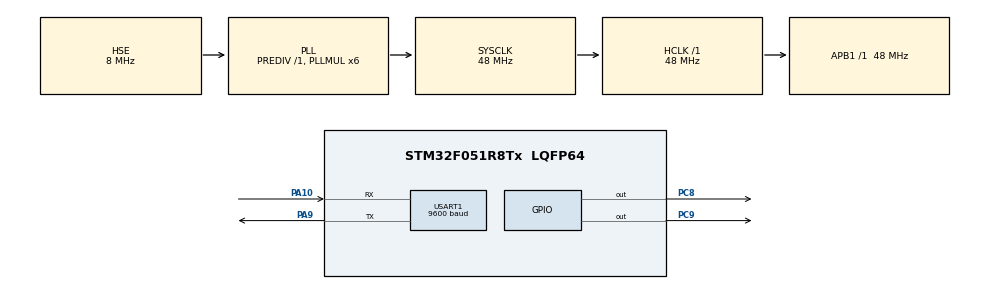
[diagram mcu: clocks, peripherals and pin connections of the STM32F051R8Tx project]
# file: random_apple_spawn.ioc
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Dma.Request0=USART1_RX
Dma.USART1_RX.0.Direction=DMA_PERIPH_TO_MEMORY
Dma.USART1_RX.0.Instance=DMA1_Channel3
Dma.USART1_RX.0.MemDataAlignment=DMA_MDATAALIGN_BYTE
Dma.USART1_RX.0.MemInc=DMA_MINC_ENABLE
Dma.USART1_RX.0.Mode=DMA_NORMAL
Dma.USART1_RX.0.PeriphDataAlignment=DMA_PDATAALIGN_BYTE
Dma.USART1_RX.0.PeriphInc=DMA_PINC_DISABLE
Dma.USART1_RX.0.Priority=DMA_PRIORITY_LOW
Mcu.Family=STM32F0
Mcu.Name=STM32F051R8Tx
Mcu.Package=LQFP64
NVIC.DMA1_Channel2_3_IRQn=true\:0\:0\:false\:false\:true\:false\:true\:true
NVIC.USART1_IRQn=true\:0\:0\:false\:false\:true\:true\:true\:true
PA10.Mode=Asynchronous
PA10.Signal=USART1_RX
PA13.Mode=Serial_Wire
PA13.Signal=SYS_SWDIO
PA14.Mode=Serial_Wire
PA14.Signal=SYS_SWCLK
PA9.Mode=Asynchronous
PA9.Signal=USART1_TX
PC8.Signal=GPIO_Output
PC9.Signal=GPIO_Output
PF0-OSC_IN.Mode=HSE-External-Oscillator
PF0-OSC_IN.Signal=RCC_OSC_IN
PF1-OSC_OUT.Mode=HSE-External-Oscillator
PF1-OSC_OUT.Signal=RCC_OSC_OUT
ProjectManager.HeapSize=0x200
ProjectManager.StackSize=0x400
ProjectManager.TargetToolchain=STM32CubeIDE
RCC.AHBFreq_Value=48000000
RCC.APB1Freq_Value=48000000
RCC.APB1TimFreq_Value=48000000
RCC.HCLKFreq_Value=48000000
RCC.PLLMUL=RCC_PLL_MUL6
RCC.PLLSourceVirtual=RCC_PLLSOURCE_HSE
RCC.SYSCLKFreq_VALUE=48000000
RCC.SYSCLKSource=RCC_SYSCLKSOURCE_PLLCLK
USART1.BaudRate=9600
USART1.VirtualMode-Asynchronous=VM_ASYNC
board=custom

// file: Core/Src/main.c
/* USER CODE BEGIN Header */
/**
  ******************************************************************************
  * @file           : main.c
  * @brief          : Main program body
  ******************************************************************************
  * @attention
  *
  * Copyright (c) 2025 STMicroelectronics.
  * All rights reserved.
  *
  * This software is licensed under terms that can be found in the LICENSE file
  * in the root directory of this software component.
  * If no LICENSE file comes with this software, it is provided AS-IS.
  *
  ******************************************************************************
  */
/* USER CODE END Header */
#include "main.h"
#include <stdio.h>
#include <stdlib.h>  // Для rand()
#include <time.h>    // Для ініціалізації випадкових чисел

UART_HandleTypeDef huart1;
DMA_HandleTypeDef hdma_usart1_rx;
uint8_t rxdata; // Буфер для прийому UART
int apple_x = 0, apple_y = 0; // Координати яблука

void SystemClock_Config(void);
static void MX_GPIO_Init(void);
static void MX_DMA_Init(void);
static void MX_USART1_UART_Init(void);
void generate_apple();
/* USER CODE BEGIN PFP */
void HAL_UART_RxCpltCallback(UART_HandleTypeDef *huart) {
    if (huart->Instance == USART1) {
        if (rxdata == 'E' || rxdata == 'e') { // Якщо натиснули E
            generate_apple(); // Генеруємо яблуко
        }
        HAL_UART_Receive_IT(&huart1, &rxdata, 1); // Продовжуємо прийом
    }
}

/* USER CODE END PFP */

/* USER CODE BEGIN 0 */
void generate_apple() {
    apple_x = rand() % 20; // Діапазон 0-19
    apple_y = rand() % 15; // Діапазон 0-14
    char buffer[30];
    int len = snprintf(buffer, sizeof(buffer), "Apple: X=%d, Y=%d\r\n", apple_x, apple_y);
    HAL_UART_Transmit(&huart1, (uint8_t *)buffer, len, HAL_MAX_DELAY);
}
/* USER CODE END 0 */

int main(void)
{

  /* MCU Configuration--------------------------------------------------------*/

  /* Reset of all peripherals, Initializes the Flash interface and the Systick. */
  HAL_Init();

  /* Configure the system clock */
  SystemClock_Config();

  /* Initialize all configured peripherals */
  MX_GPIO_Init();
  MX_DMA_Init();
  MX_USART1_UART_Init();
  srand(HAL_GetTick()); // Ініціалізація випадкових чисел

  /* Infinite loop */
  while (1)
  {
	  HAL_Delay(100); // Маленька пауза для стабільності
  }
}

void SystemClock_Config(void)
{
  RCC_OscInitTypeDef RCC_OscInitStruct = {0};
  RCC_ClkInitTypeDef RCC_ClkInitStruct = {0};
  RCC_PeriphCLKInitTypeDef PeriphClkInit = {0};

  /** Initializes the RCC Oscillators according to the specified parameters
  * in the RCC_OscInitTypeDef structure.
  */
  RCC_OscInitStruct.OscillatorType = RCC_OSCILLATORTYPE_HSE;
  RCC_OscInitStruct.HSEState = RCC_HSE_ON;
  RCC_OscInitStruct.PLL.PLLState = RCC_PLL_ON;
  RCC_OscInitStruct.PLL.PLLSource = RCC_PLLSOURCE_HSE;
  RCC_OscInitStruct.PLL.PLLMUL = RCC_PLL_MUL6;
  RCC_OscInitStruct.PLL.PREDIV = RCC_PREDIV_DIV1;
  if (HAL_RCC_OscConfig(&RCC_OscInitStruct) != HAL_OK)
  {
    Error_Handler();
  }

  /** Initializes the CPU, AHB and APB buses clocks
  */
  RCC_ClkInitStruct.ClockType = RCC_CLOCKTYPE_HCLK|RCC_CLOCKTYPE_SYSCLK
                              |RCC_CLOCKTYPE_PCLK1;
  RCC_ClkInitStruct.SYSCLKSource = RCC_SYSCLKSOURCE_PLLCLK;
  RCC_ClkInitStruct.AHBCLKDivider = RCC_SYSCLK_DIV1;
  RCC_ClkInitStruct.APB1CLKDivider = RCC_HCLK_DIV1;

  if (HAL_RCC_ClockConfig(&RCC_ClkInitStruct, FLASH_LATENCY_1) != HAL_OK)
  {
    Error_Handler();
  }
  PeriphClkInit.PeriphClockSelection = RCC_PERIPHCLK_USART1;
  PeriphClkInit.Usart1ClockSelection = RCC_USART1CLKSOURCE_PCLK1;
  if (HAL_RCCEx_PeriphCLKConfig(&PeriphClkInit) != HAL_OK)
  {
    Error_Handler();
  }
}

static void MX_USART1_UART_Init(void)
{

  huart1.Instance = USART1;
  huart1.Init.BaudRate = 9600;
  huart1.Init.WordLength = UART_WORDLENGTH_8B;
  huart1.Init.StopBits = UART_STOPBITS_1;
  huart1.Init.Parity = UART_PARITY_NONE;
  huart1.Init.Mode = UART_MODE_TX_RX;
  huart1.Init.HwFlowCtl = UART_HWCONTROL_NONE;
  huart1.Init.OverSampling = UART_OVERSAMPLING_16;
  huart1.Init.OneBitSampling = UART_ONE_BIT_SAMPLE_DISABLE;
  huart1.AdvancedInit.AdvFeatureInit = UART_ADVFEATURE_NO_INIT;
  if (HAL_UART_Init(&huart1) != HAL_OK)
  {
    Error_Handler();
  }

}

static void MX_DMA_Init(void)
{

  /* DMA controller clock enable */
  __HAL_RCC_DMA1_CLK_ENABLE();

  /* DMA interrupt init */
  /* DMA1_Channel2_3_IRQn interrupt configuration */
  HAL_NVIC_SetPriority(DMA1_Channel2_3_IRQn, 0, 0);
  HAL_NVIC_EnableIRQ(DMA1_Channel2_3_IRQn);

}

static void MX_GPIO_Init(void)
{
  GPIO_InitTypeDef GPIO_InitStruct = {0};

  /* GPIO Ports Clock Enable */
  __HAL_RCC_GPIOF_CLK_ENABLE();
  __HAL_RCC_GPIOC_CLK_ENABLE();
  __HAL_RCC_GPIOA_CLK_ENABLE();

  /*Configure GPIO pin Output Level */
  HAL_GPIO_WritePin(GPIOC, GPIO_PIN_8|GPIO_PIN_9, GPIO_PIN_RESET);

  /*Configure GPIO pins : PC8 PC9 */
  GPIO_InitStruct.Pin = GPIO_PIN_8|GPIO_PIN_9;
  GPIO_InitStruct.Mode = GPIO_MODE_OUTPUT_PP;
  GPIO_InitStruct.Pull = GPIO_NOPULL;
  GPIO_InitStruct.Speed = GPIO_SPEED_FREQ_LOW;
  HAL_GPIO_Init(GPIOC, &GPIO_InitStruct);

}

void Error_Handler(void)
{
  __disable_irq();
  while (1)
  {
  }
}
